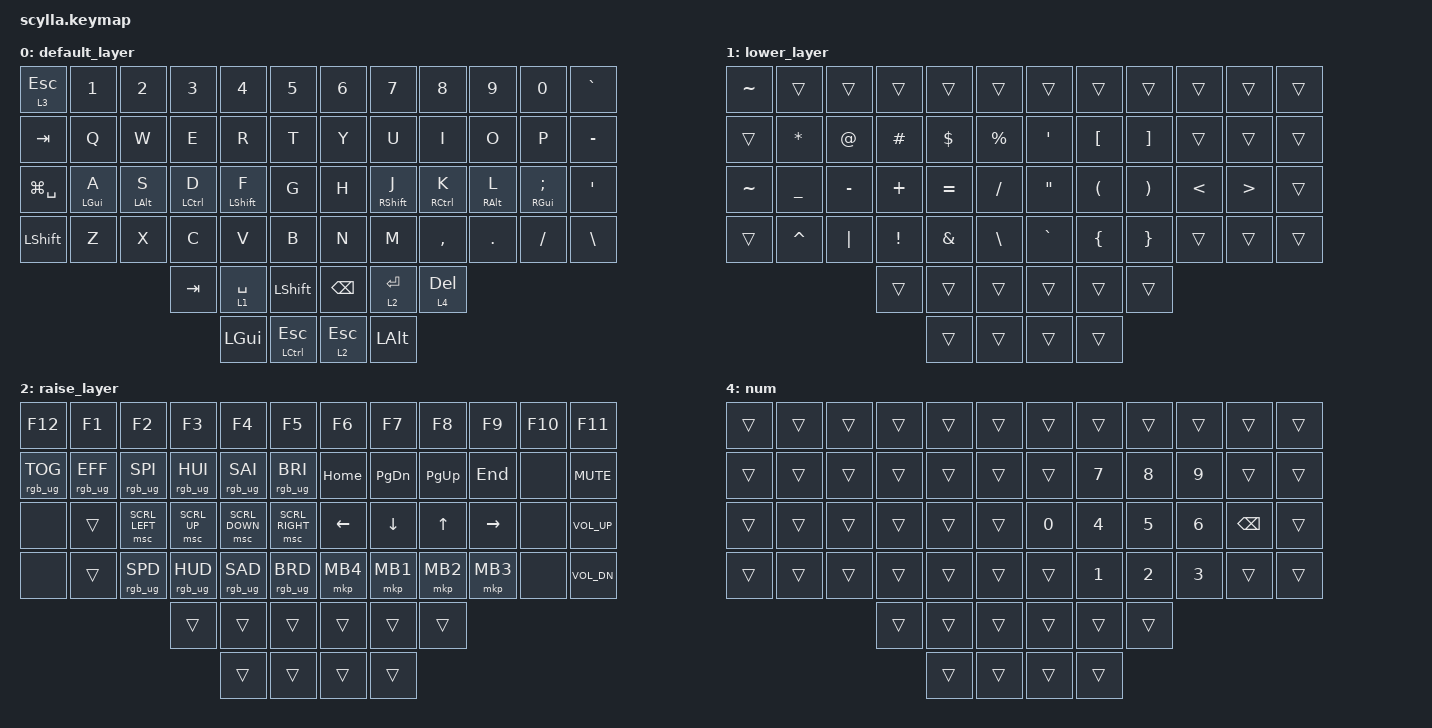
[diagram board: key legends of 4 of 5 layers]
#include <behaviors.dtsi>
#include <dt-bindings/zmk/bt.h>
#include <dt-bindings/zmk/keys.h>
#include <dt-bindings/zmk/outputs.h>
#include <dt-bindings/zmk/pointing.h>
#include <dt-bindings/zmk/rgb.h>

#define DEFAULT 0
#define LWR 1
#define RSE 2
#define ADJ 3

/ {
    combos {
        compatible = "zmk,combos";

        combo1 {
            bindings = <&kp LBKT>;
            key-positions = <15 16>;
        };

        combo2 {
            bindings = <&kp RBKT>;
            key-positions = <19 20>;
        };

        combo3 {
            bindings = <&kp LEFT_PARENTHESIS>;
            key-positions = <27 28>;
        };

        combo4 {
            bindings = <&kp RIGHT_PARENTHESIS>;
            key-positions = <31 32>;
        };

        combo5 {
            bindings = <&kp LEFT_BRACE>;
            key-positions = <39 40>;
        };

        combo6 {
            bindings = <&kp RIGHT_BRACE>;
            key-positions = <43 44>;
        };

        combo7 {
            bindings = <&kp BACKSLASH>;
            key-positions = <17 18>;
        };

        combo8 {
            bindings = <&kp PIPE>;
            key-positions = <29 30>;
        };

        combo9 {
            bindings = <&kp ESC>;
            key-positions = <13 14>;
        };

        combo10 {
            bindings = <&kp TAB>;
            key-positions = <25 26>;
        };
    };

    behaviors {
        ltq: ltq {
            compatible = "zmk,behavior-hold-tap";
            label = "LTQ";
            bindings = <&mo>, <&kp>;

            #binding-cells = <2>;
            tapping-term-ms = <200>;
            quick-tap-ms = <180>;
            global-quick-tap;
        };
    };

    keymap {
        compatible = "zmk,keymap";

        default_layer {
            bindings = <
&lt 3 ESCAPE    &kp N1      &kp N2      &kp N3       &kp N4            &kp N5              &kp N6         &kp N7             &kp N8       &kp N9           &kp N0                   &kp GRAVE
&kp TAB         &kp Q       &kp W       &kp E        &kp R             &kp T               &kp Y          &kp U              &kp I        &kp O            &kp P                    &kp MINUS
&kp LG(SPACE)   &mt LGUI A  &mt LALT S  &mt LCTRL D  &mt LEFT_SHIFT F  &kp G               &kp H          &mt RIGHT_SHIFT J  &mt RCTRL K  &mt RIGHT_ALT L  &mt RIGHT_GUI SEMICOLON  &kp SQT
&kp LEFT_SHIFT  &kp Z       &kp X       &kp C        &kp V             &kp B               &kp N          &kp M              &kp COMMA    &kp DOT          &kp FSLH                 &kp BSLH
                                        &kp TAB      &lt 1 SPACE       &kp LEFT_SHIFT      &kp BACKSPACE  &lt 2 ENTER        &lt 4 DEL
                                                     &kp LEFT_GUI      &mt LCTRL ESCAPE    &lt 2 ESCAPE   &kp LEFT_ALT
            >;
        };

        lower_layer {
            bindings = <
&kp TILDE  &trans     &trans     &trans    &trans      &trans           &trans             &trans                &trans                 &trans         &trans            &trans
&trans     &kp ASTRK  &kp AT     &kp HASH  &kp DOLLAR  &kp PERCENT      &kp SINGLE_QUOTE   &kp LEFT_BRACKET      &kp RIGHT_BRACKET      &trans         &trans            &trans
&kp TILDE  &kp UNDER  &kp MINUS  &kp PLUS  &kp EQUAL   &kp SLASH        &kp DOUBLE_QUOTES  &kp LEFT_PARENTHESIS  &kp RIGHT_PARENTHESIS  &kp LESS_THAN  &kp GREATER_THAN  &trans
&trans     &kp CARET  &kp PIPE   &kp EXCL  &kp AMPS    &kp BACKSLASH    &kp GRAVE          &kp LEFT_BRACE        &kp RIGHT_BRACE        &trans         &trans            &trans
                                 &trans    &trans      &trans           &trans             &trans                &trans
                                           &trans      &trans           &trans             &trans
            >;
        };

        raise_layer {
            bindings = <
&kp F12          &kp F1           &kp F2           &kp F3           &kp F4           &kp F5             &kp F6          &kp F7         &kp F8        &kp F9     &kp F10  &kp F11
&rgb_ug RGB_TOG  &rgb_ug RGB_EFF  &rgb_ug RGB_SPI  &rgb_ug RGB_HUI  &rgb_ug RGB_SAI  &rgb_ug RGB_BRI    &kp HOME        &kp PAGE_DOWN  &kp PAGE_UP   &kp END    &none    &kp C_MUTE
&none            &trans           &msc SCRL_LEFT   &msc SCRL_UP     &msc SCRL_DOWN   &msc SCRL_RIGHT    &kp LEFT_ARROW  &kp DOWN       &kp UP_ARROW  &kp RIGHT  &none    &kp C_VOL_UP
&none            &trans           &rgb_ug RGB_SPD  &rgb_ug RGB_HUD  &rgb_ug RGB_SAD  &rgb_ug RGB_BRD    &mkp MB4        &mkp MB1       &mkp MB2      &mkp MB3   &none    &kp C_VOL_DN
                                                   &trans           &trans           &trans             &trans          &trans         &trans
                                                                    &trans           &trans             &trans          &trans
            >;
        };

        adjust_layer {
            bindings = <
&none  &bt BT_SEL 0  &bt BT_SEL 1  &bt BT_SEL 2  &bt BT_SEL 3  &bt BT_SEL 4    &none  &none  &none  &none  &none  &none
&none  &bt BT_CLR    &none         &none         &none         &none           &none  &none  &none  &none  &none  &none
&none  &none         &none         &none         &none         &none           &none  &none  &none  &none  &none  &none
&none  &none         &none         &none         &none         &out OUT_TOG    &none  &none  &none  &none  &none  &none
                                   &none         &none         &none           &none  &none  &none
                                                 &none         &none           &none
            >;
        };

        num {
            bindings = <
&trans  &trans  &trans  &trans  &trans  &trans    &trans  &trans  &trans  &trans  &trans    &trans
&trans  &trans  &trans  &trans  &trans  &trans    &trans  &kp N7  &kp N8  &kp N9  &trans    &trans
&trans  &trans  &trans  &trans  &trans  &trans    &kp N0  &kp N4  &kp N5  &kp N6  &kp BSPC  &trans
&trans  &trans  &trans  &trans  &trans  &trans    &trans  &kp N1  &kp N2  &kp N3  &trans    &trans
                        &trans  &trans  &trans    &trans  &trans  &trans
                                &trans  &trans    &trans  &trans
            >;
        };
    };
};

